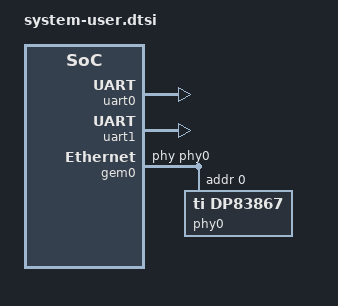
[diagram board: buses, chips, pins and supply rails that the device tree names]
/include/ "system-conf.dtsi"
/ {
     aliases {
        serial0 = &uart0;
        serial1 = &uart1;
    };
 
    chosen {
        bootargs = "console=ttyPS0,115200 earlyprintk root=/dev/mmcblk0p2 rw rootwait earlycon";
        linux,stdout-path = "serial0:115200n8";
    };
    
};

&uart0 {
	status = "okay";
	interrupts = <0x0 0x1b 0x4>;
	device_type = "serial";
     port-number = <0x0>;
};

&uart1 {
	status = "okay";
	interrupts = <0x0 0x32 0x4>;
	device_type = "serial";
    port-number = <0x1>;
};

&gem0 {
    status = "okay";
    phy-handle = <&phy0>;
    phy0: phy@0 {
        reg = <0>;
        compatible = "ti,dp83867", "ethernet-phy-ieee802.3-c22"; 
        ti,rx-internal-delay = <0x8>; 
        ti,tx-internal-delay = <0xa>; 
        ti,fifo-depth = <0x01>; 
    };
};


&amba_pl{
    compatible = "xlnx,zynq";
 };
